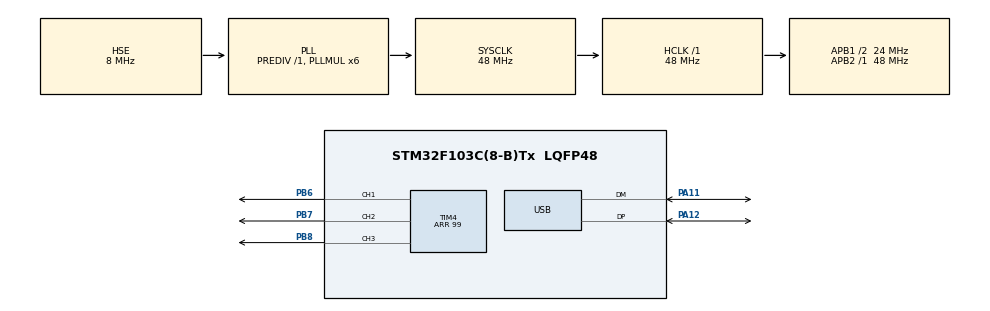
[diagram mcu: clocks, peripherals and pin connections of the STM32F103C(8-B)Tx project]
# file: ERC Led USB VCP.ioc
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Mcu.Family=STM32F1
Mcu.Name=STM32F103C(8-B)Tx
Mcu.Package=LQFP48
NVIC.PriorityGroup=NVIC_PRIORITYGROUP_4
NVIC.TIM4_IRQn=true\:0\:0\:false\:false\:true\:true\:true\:true
NVIC.USB_LP_CAN1_RX0_IRQn=true\:0\:0\:false\:false\:true\:false\:true\:true
PA11.Mode=Device
PA11.Signal=USB_DM
PA12.Mode=Device
PA12.Signal=USB_DP
PA13.Mode=Serial_Wire
PA13.Signal=SYS_JTMS-SWDIO
PA14.Mode=Serial_Wire
PA14.Signal=SYS_JTCK-SWCLK
PB6.Signal=S_TIM4_CH1
PB7.Signal=S_TIM4_CH2
PB8.Signal=S_TIM4_CH3
PD0-OSC_IN.Mode=HSE-External-Oscillator
PD0-OSC_IN.Signal=RCC_OSC_IN
PD1-OSC_OUT.Mode=HSE-External-Oscillator
PD1-OSC_OUT.Signal=RCC_OSC_OUT
ProjectManager.HeapSize=0x200
ProjectManager.StackSize=0x400
ProjectManager.TargetToolchain=STM32CubeIDE
RCC.AHBFreq_Value=48000000
RCC.APB1CLKDivider=RCC_HCLK_DIV2
RCC.APB1Freq_Value=24000000
RCC.APB1TimFreq_Value=48000000
RCC.APB2Freq_Value=48000000
RCC.APB2TimFreq_Value=48000000
RCC.HCLKFreq_Value=48000000
RCC.PLLMUL=RCC_PLL_MUL6
RCC.SYSCLKFreq_VALUE=48000000
RCC.SYSCLKSource=RCC_SYSCLKSOURCE_PLLCLK
RCC.USBFreq_Value=48000000
SH.S_TIM4_CH1.0=TIM4_CH1,PWM Generation1 CH1
SH.S_TIM4_CH2.0=TIM4_CH2,PWM Generation2 CH2
SH.S_TIM4_CH3.0=TIM4_CH3,PWM Generation3 CH3
TIM4.AutoReloadPreload=TIM_AUTORELOAD_PRELOAD_ENABLE
TIM4.Channel-PWM\ Generation1\ CH1=TIM_CHANNEL_1
TIM4.Channel-PWM\ Generation2\ CH2=TIM_CHANNEL_2
TIM4.Channel-PWM\ Generation3\ CH3=TIM_CHANNEL_3
TIM4.Period=99
TIM4.Pulse-PWM\ Generation1\ CH1=99
TIM4.Pulse-PWM\ Generation2\ CH2=99
TIM4.Pulse-PWM\ Generation3\ CH3=99
USB_DEVICE.CLASS_NAME_FS=CDC
USB_DEVICE.VirtualMode=Cdc
USB_DEVICE.VirtualModeFS=Cdc_FS
VP_USB_DEVICE_VS_USB_DEVICE_CDC_FS.Mode=CDC_FS
board=custom

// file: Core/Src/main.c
/* USER CODE BEGIN Header */
/**
  ******************************************************************************
  * @file           : main.c
  * @brief          : Main program body
  ******************************************************************************
  * @attention
  *
  * Copyright (c) 2024 STMicroelectronics.
  * All rights reserved.
  *
  * This software is licensed under terms that can be found in the LICENSE file
  * in the root directory of this software component.
  * If no LICENSE file comes with this software, it is provided AS-IS.
  *
  ******************************************************************************
  */
/* USER CODE END Header */
#include "main.h"
#include "usb_device.h"

TIM_HandleTypeDef htim4;

/* USER CODE BEGIN PV */
uint32_t compare_value_r;
uint32_t compare_value_g;
uint32_t compare_value_b;
/* USER CODE END PV */

void SystemClock_Config(void);
static void MX_GPIO_Init(void);
static void MX_TIM4_Init(void);

int main(void)
{

  /* MCU Configuration--------------------------------------------------------*/

  /* Reset of all peripherals, Initializes the Flash interface and the Systick. */
  HAL_Init();

  /* Configure the system clock */
  SystemClock_Config();

  /* Initialize all configured peripherals */
  MX_GPIO_Init();
  MX_TIM4_Init();
  MX_USB_DEVICE_Init();
  /* USER CODE BEGIN 2 */
  HAL_TIM_Base_Start(&htim4);
  HAL_TIM_PWM_Start(&htim4, TIM_CHANNEL_1);
  HAL_TIM_PWM_Start(&htim4, TIM_CHANNEL_2);
  HAL_TIM_PWM_Start(&htim4, TIM_CHANNEL_3);
  /* USER CODE END 2 */

  /* Infinite loop */
  /* USER CODE BEGIN WHILE */
  while (1)
  {
	  __HAL_TIM_SET_COMPARE(&htim4, TIM_CHANNEL_1, compare_value_r);
	  __HAL_TIM_SET_COMPARE(&htim4, TIM_CHANNEL_2, compare_value_b);
	  __HAL_TIM_SET_COMPARE(&htim4, TIM_CHANNEL_3, compare_value_g);
    /* USER CODE END WHILE */

  }
}

void SystemClock_Config(void)
{
  RCC_OscInitTypeDef RCC_OscInitStruct = {0};
  RCC_ClkInitTypeDef RCC_ClkInitStruct = {0};
  RCC_PeriphCLKInitTypeDef PeriphClkInit = {0};

  /** Initializes the RCC Oscillators according to the specified parameters
  * in the RCC_OscInitTypeDef structure.
  */
  RCC_OscInitStruct.OscillatorType = RCC_OSCILLATORTYPE_HSE;
  RCC_OscInitStruct.HSEState = RCC_HSE_ON;
  RCC_OscInitStruct.HSEPredivValue = RCC_HSE_PREDIV_DIV1;
  RCC_OscInitStruct.HSIState = RCC_HSI_ON;
  RCC_OscInitStruct.PLL.PLLState = RCC_PLL_ON;
  RCC_OscInitStruct.PLL.PLLSource = RCC_PLLSOURCE_HSE;
  RCC_OscInitStruct.PLL.PLLMUL = RCC_PLL_MUL6;
  if (HAL_RCC_OscConfig(&RCC_OscInitStruct) != HAL_OK)
  {
    Error_Handler();
  }

  /** Initializes the CPU, AHB and APB buses clocks
  */
  RCC_ClkInitStruct.ClockType = RCC_CLOCKTYPE_HCLK|RCC_CLOCKTYPE_SYSCLK
                              |RCC_CLOCKTYPE_PCLK1|RCC_CLOCKTYPE_PCLK2;
  RCC_ClkInitStruct.SYSCLKSource = RCC_SYSCLKSOURCE_PLLCLK;
  RCC_ClkInitStruct.AHBCLKDivider = RCC_SYSCLK_DIV1;
  RCC_ClkInitStruct.APB1CLKDivider = RCC_HCLK_DIV2;
  RCC_ClkInitStruct.APB2CLKDivider = RCC_HCLK_DIV1;

  if (HAL_RCC_ClockConfig(&RCC_ClkInitStruct, FLASH_LATENCY_1) != HAL_OK)
  {
    Error_Handler();
  }
  PeriphClkInit.PeriphClockSelection = RCC_PERIPHCLK_USB;
  PeriphClkInit.UsbClockSelection = RCC_USBCLKSOURCE_PLL;
  if (HAL_RCCEx_PeriphCLKConfig(&PeriphClkInit) != HAL_OK)
  {
    Error_Handler();
  }
}

static void MX_TIM4_Init(void)
{

  TIM_MasterConfigTypeDef sMasterConfig = {0};
  TIM_OC_InitTypeDef sConfigOC = {0};

  htim4.Instance = TIM4;
  htim4.Init.Prescaler = 0;
  htim4.Init.CounterMode = TIM_COUNTERMODE_UP;
  htim4.Init.Period = 99;
  htim4.Init.ClockDivision = TIM_CLOCKDIVISION_DIV1;
  htim4.Init.AutoReloadPreload = TIM_AUTORELOAD_PRELOAD_ENABLE;
  if (HAL_TIM_PWM_Init(&htim4) != HAL_OK)
  {
    Error_Handler();
  }
  sMasterConfig.MasterOutputTrigger = TIM_TRGO_RESET;
  sMasterConfig.MasterSlaveMode = TIM_MASTERSLAVEMODE_DISABLE;
  if (HAL_TIMEx_MasterConfigSynchronization(&htim4, &sMasterConfig) != HAL_OK)
  {
    Error_Handler();
  }
  sConfigOC.OCMode = TIM_OCMODE_PWM1;
  sConfigOC.Pulse = 99;
  sConfigOC.OCPolarity = TIM_OCPOLARITY_HIGH;
  sConfigOC.OCFastMode = TIM_OCFAST_DISABLE;
  if (HAL_TIM_PWM_ConfigChannel(&htim4, &sConfigOC, TIM_CHANNEL_1) != HAL_OK)
  {
    Error_Handler();
  }
  if (HAL_TIM_PWM_ConfigChannel(&htim4, &sConfigOC, TIM_CHANNEL_2) != HAL_OK)
  {
    Error_Handler();
  }
  if (HAL_TIM_PWM_ConfigChannel(&htim4, &sConfigOC, TIM_CHANNEL_3) != HAL_OK)
  {
    Error_Handler();
  }
  HAL_TIM_MspPostInit(&htim4);

}

static void MX_GPIO_Init(void)
{

  /* GPIO Ports Clock Enable */
  __HAL_RCC_GPIOD_CLK_ENABLE();
  __HAL_RCC_GPIOA_CLK_ENABLE();
  __HAL_RCC_GPIOB_CLK_ENABLE();

}

void Error_Handler(void)
{
  __disable_irq();
  while (1)
  {
  }
}
